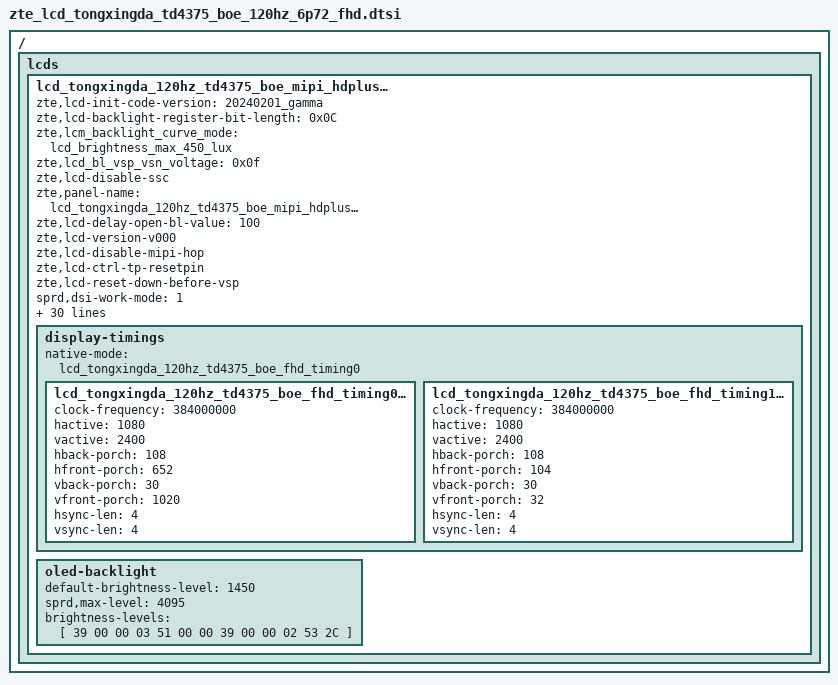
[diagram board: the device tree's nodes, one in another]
/ {
	fragment {
		target-path = "/";
		__overlay__ {
			lcds {
				lcd_tongxingda_120hz_td4375_boe_mipi_hdplus_omnivision: lcd_tongxingda_120hz_td4375_boe_mipi_hdplus_omnivision {
					zte,lcd-init-code-version = "20240201_gamma";

					zte,lcd-backlight-register-bit-length = <0x0C>;
					zte,lcm_backlight_curve_mode = "lcd_brightness_max_450_lux";
					zte,lcd_bl_vsp_vsn_voltage = <0x0f>;
					zte,lcd-disable-ssc;
					zte,panel-name = "lcd_tongxingda_120hz_td4375_boe_mipi_hdplus_omnivision";
					zte,lcd-delay-open-bl-value = <100>;
					zte,lcd-version-v000;
					zte,lcd-disable-mipi-hop;
					zte,lcd-ctrl-tp-resetpin;
					zte,lcd-reset-down-before-vsp;

					sprd,dsi-work-mode = <1>;
					sprd,dsi-lane-number = <4>;
					sprd,dsi-color-format = "dsc";
					sprd,phy-bit-clock = <1100000>;
					sprd,phy-escape-clock = <20000>;/* kHz */

					sprd,width-mm = <70081>;
					sprd,height-mm = <155736>;
					sprd,vrr-enabled;
					sprd,vrr-max-layers = <3>;
					sprd,slice-width = <540>;
					sprd,slice-height = <12>;
					sprd,output-bpc = <8>;
					sprd,dsc-enable = <1>;
					sprd,dual-dsi-enable = <0>;

					sprd,esd-check-enable = <1>;/* 0:close , 1:open */
					sprd,esd-check-mode = <1>;/* 0:REG ,1:TE  */
					sprd,esd-check-period = <2000>;
					sprd,esd-check-register = <0x0A>;
					sprd,esd-check-value = <0x9C>;

					sprd,dphy-taget-val = <5>;

					sprd,reset-on-sequence = <1 5>, <0 15>, <1 25>;
					sprd,reset-off-sequence = <0 20>;

					sprd,use-gen-write;
					sprd,initial-command = [
39 00 00 02 B0 00
39 00 00 0B B6 30 6B 00 86 03 0A 13 1A 00 00
39 00 00 05 B7 51 00 00 00
39 00 00 08 B8 57 3D 19 BE 1E 0A 0A
39 00 00 08 B9 6F 3D 28 BE 3C 14 0A
39 00 00 08 BA 33 57 00 00 00 00 0A
39 00 00 0C BB 44 26 C3 1F 19 06 03 C0 00 00 10
39 00 00 0C BC 32 4C C3 52 32 1F 03 F2 00 00 13
39 00 00 0C BD 24 68 C3 AA 3F 32 03 FF 00 00 25
39 00 00 0D BE 00 00 00 00 00 00 00 00 00 00 00 00
39 00 00 18 C0 00 60 01 2C 14 09 60 03 B6 22 00 08 00 70 00 00 00 00 00 00 00 00 02
39 00 00 35 C1 30 00 00 81 00 00 00 00 22 00 05 20 00 80 FA 40 00 84 0F 00 00 00 00 00 00 00 00 00 00 00 00 00 00 00 00 00 00 00 00 00 00 01 2C 08 08 00 09 C4 0D 66 14 50
39 00 00 8E C2 00 50 5D 02 02 10 03 05 00 00 00 00 00 00 00 00 00 00 00 00 00 00 00 00 00 00 00 00 30 5D 04 04 01 01 C1 00 A0 0A 00 00 02 08 00 00 00 00 11 00 A0 0A 04 00 00 00 00 00 00 00 00 00 00 00 00 00 00 00 00 00 00 00 00 00 11 00 00 00 00 00 00 00 00 00 00 00 00 00 00 00 00 00 00 00 00 00 00 00 11 00 00 00 00 00 00 00 00 00 00 00 00 00 00 00 00 00 00 00 00 00 00 00 11 00 00 00 00 00 00 00 00 00 00 00 00 00 00 00 00 00 00 00 00
39 00 00 6D C3 00 00 61 01 00 00 04 00 00 00 00 00 CE 01 00 0A 01 00 00 00 00 00 00 00 00 00 00 00 00 00 00 00 00 00 00 00 00 00 00 00 00 00 00 00 00 00 00 00 00 00 00 00 00 00 00 00 00 00 00 00 00 00 AA AA AA 00 00 00 00 00 00 01 00 01 00 00 02 00 00 C0 00 08 00 50 00 00 01 00 00 C0 00 08 00 50 00 00 01 00 00 C0 00 00 00 00 00 00 00 00
39 00 00 6E C4 00 00 00 61 5F 5D 00 0F 0E 11 10 00 4F BF 00 53 00 BE 4D 4D 44 03 02 51 00 00 00 61 5F 5D 00 0F 0E 11 10 00 4F BF 00 53 00 BE 4D 4D 44 03 02 51 FF FF FF FF FF FF B8 87 7C B8 87 7C 00 30 82 00 30 82 38 00 00 38 00 00 00 00 00 00 00 00 00 00 00 00 00 00 00 00 00 00 00 58 55 00 00 00 00 00 00 00 00 00 00 00 00 00 00 00 00 00 00
39 00 00 06 C5 08 00 00 00 00
39 00 00 3F C6 02 0A 08 FC FF FF FF 00 00 13 01 AF 00 01 05 1C 1C 1C 00 00 00 34 05 09 28 28 01 05 1C 1C 1C 01 0B 00 00 00 1E 01 00 00 00 00 00 00 20 20 00 00 00 00 00 00 00 00 22 22 00 00 00 00 10 00
39 00 00 0F CB 20 80 70 00 20 00 00 2D 41 00 00 00 00 FF
39 00 00 02 CD 00
39 00 00 24 CE 75 40 49 53 59 5E 63 68 6E 74 7E 8A 98 A8 BB D0 E7 FF 00 6D 02 02 45 04 69 5A 40 51 F4 00 00 84 FA 00 00
39 00 00 07 CF 89 00 80 46 61 00
39 00 00 13 D0 CC 1E D5 66 09 B0 00 CF EF E5 D4 0B 52 FE 09 09 CF 00
39 00 00 2C D1 D7 D7 1B B0 07 07 3B 44 34 44 34 05 33 7B 07 33 3B 78 D2 D2 06 96 13 93 22 22 22 B3 BB 80 00 BB BB 11 08 08 84 C0 09 77 FF 11 44
39 00 00 03 D2 00 00
39 00 00 18 D4 00 00 00 00 00 00 00 00 00 00 00 00 00 00 00 00 00 00 00 00 00 00 00
39 00 00 4B D7 21 10 52 52 00 60 00 0C 00 60 04 FD 01 00 03 00 05 05 00 03 04 05 00 04 00 08 02 08 06 03 08 04 08 10 0C 0B 0A 0A 0A 07 07 06 06 00 08 08 04 05 09 00 04 04 04 04 04 04 04 02 04 04 04 04 04 04 04 04 04 04 06 06 05 05 05 00
39 00 00 3F D8 00 12 00 00 00 00 00 00 00 00 00 00 00 00 00 00 00 00 00 00 00 00 00 00 00 00 00 00 00 00 00 00 00 00 00 00 00 00 00 00 00 00 00 00 00 00 00 00 00 00 00 00 00 00 00 00 00 00 00 00 00 00
39 00 00 17 D9 40 99 26 ED 16 6C 16 6C 16 6C 00 14 00 14 00 14 01 0C 00 00 01 00
39 00 00 05 DD 30 06 23 65
39 00 00 0B DE 00 00 00 0F FF 00 00 00 00 10
39 00 00 0B E6 00 00 00 00 00 00 00 00 00 00
39 00 00 B7 E7 11 00 89 30 80 09 60 04 38 00 0C 02 1C 02 1C 02 00 02 0E 20 01 1F 00 07 0C 08 BB 08 7A 18 00 10 F0 03 0C 20 00 06 0B 0B 33 0E 1C 2A 38 46 54 62 69 70 77 79 7B 7D 7E 01 02 01 00 09 40 09 BE 19 FC 19 FA 19 F8 1A 38 1A 78 1A B6 2A F6 2B 34 2B 74 3B 74 6B F4 00 00 00 00 00 00 11 00 89 30 80 09 60 04 38 00 0C 02 1C 02 1C 02 00 02 0E 20 01 1F 00 07 0C 08 BB 08 7A 18 00 10 F0 03 0C 20 00 06 0B 0B 33 0E 1C 2A 38 46 54 62 69 70 77 79 7B 7D 7E 01 02 01 00 09 40 09 BE 19 FC 19 FA 19 F8 1A 38 1A 78 1A B6 2A F6 2B 34 2B 74 3B 74 6B F4 00 00 00 00 00 00
39 00 00 05 E8 00 30 63 00
39 00 00 1F EA 01 0E 02 00 0F 00 00 00 19 0A 01 AB 00 00 00 00 00 00 00 00 04 C2 00 12 00 60 06 00 86 00
39 00 00 08 EB 00 00 00 00 01 00 11
39 00 00 0B EC 03 70 00 10 82 0F 00 00 02 3A
39 00 00 21 ED 01 01 02 02 00 00 00 00 00 00 00 00 02 00 00 00 00 00 00 00 00 00 00 D0 00 00 00 00 00 EC 10 00
39 00 00 61 EE 03 1F 00 00 00 F5 01 00 00 00 00 C2 4F 7D F0 03 00 00 00 00 00 00 00 00 4F 3D F0 01 10 09 09 09 09 00 00 00 00 00 00 00 01 00 00 00 00 00 00 00 00 00 00 00 00 00 00 1F 00 00 00 00 00 00 00 00 00 00 00 00 00 00 00 00 00 00 00 00 00 00 00 00 00 00 00 00 00 00 00 00 00 00 00 00 00 00 00 00
39 00 00 54 EF 00 90 25 04 10 00 00 00 00 18 18 18 00 00 00 00 00 00 00 00 00 00 90 25 04 10 18 18 18 00 00 00 00 00 00 10 02 10 00 00 10 00 10 00 0A 06 40 00 00 00 00 4B 00 03 51 00 00 05 00 00 00 00 00 00 00 00 00 00 00 00 00 00 00 00 00 00 00 00 00 00 02 00 00
39 00 00 17 F1 00 00 00 00 00 00 00 00 00 00 00 00 00 00 00 00 00 00 00 00 00 00
39 00 00 09 F9 44 3F 00 8D BF 00 09 1D
39 00 00 02 B0 04
39 00 00 4D C7 00 00 00 B7 01 22 01 47 01 60 01 68 01 73 01 6F 01 89 01 58 01 AA 01 69 01 AA 01 61 01 C8 01 BC 02 32 02 9F 02 AD 00 00 00 B7 01 22 01 47 01 60 01 68 01 73 01 6F 01 89 01 58 01 AA 01 69 01 AA 01 61 01 C8 01 BC 02 32 02 9F 02 AD
39 00 00 02 B0 03
39 00 00 03 51 00 00
39 00 00 02 53 2C
39 00 00 02 55 00
39 00 00 02 35 00
05 78 00 02 11 00
05 14 00 02 29 00
					];

					zte,initial-command-fps120 = [
39 00 00 02 B0 00
39 00 00 0B B6 30 6B 00 86 03 0A 13 1A 00 00
39 00 00 05 B7 51 00 00 00
39 00 00 08 B8 57 3D 19 BE 1E 0A 0A
39 00 00 08 B9 6F 3D 28 BE 3C 14 0A
39 00 00 08 BA 33 57 00 00 00 00 0A
39 00 00 0C BB 44 26 C3 1F 19 06 03 C0 00 00 10
39 00 00 0C BC 32 4C C3 52 32 1F 03 F2 00 00 13
39 00 00 0C BD 24 68 C3 AA 3F 32 03 FF 00 00 25
39 00 00 0D BE 00 00 00 00 00 00 00 00 00 00 00 00
39 00 00 18 C0 00 60 01 2C 14 09 60 03 B6 22 00 08 00 70 00 00 00 00 00 00 00 00 02
39 00 00 35 C1 30 00 00 81 00 00 00 00 22 00 05 20 00 80 FA 40 00 84 0F 00 00 00 00 00 00 00 00 00 00 00 00 00 00 00 00 00 00 00 00 00 00 01 2C 08 08 00 09 C4 0D 66 14 50
39 00 00 8E C2 00 50 5D 02 02 10 03 05 00 00 00 00 00 00 00 00 00 00 00 00 00 00 00 00 00 00 00 00 30 5D 04 04 01 01 C1 00 A0 0A 00 00 02 08 00 00 00 00 11 00 A0 0A 04 00 00 00 00 00 00 00 00 00 00 00 00 00 00 00 00 00 00 00 00 00 11 00 00 00 00 00 00 00 00 00 00 00 00 00 00 00 00 00 00 00 00 00 00 00 11 00 00 00 00 00 00 00 00 00 00 00 00 00 00 00 00 00 00 00 00 00 00 00 11 00 00 00 00 00 00 00 00 00 00 00 00 00 00 00 00 00 00 00 00
39 00 00 6D C3 00 00 61 01 00 00 04 00 00 00 00 00 CE 01 00 0A 01 00 00 00 00 00 00 00 00 00 00 00 00 00 00 00 00 00 00 00 00 00 00 00 00 00 00 00 00 00 00 00 00 00 00 00 00 00 00 00 00 00 00 00 00 00 AA AA AA 00 00 00 00 00 00 01 00 01 00 00 02 00 00 C0 00 08 00 50 00 00 01 00 00 C0 00 08 00 50 00 00 01 00 00 C0 00 00 00 00 00 00 00 00
39 00 00 6E C4 00 00 00 61 5F 5D 00 0F 0E 11 10 00 4F BF 00 53 00 BE 4D 4D 44 03 02 51 00 00 00 61 5F 5D 00 0F 0E 11 10 00 4F BF 00 53 00 BE 4D 4D 44 03 02 51 FF FF FF FF FF FF B8 87 7C B8 87 7C 00 30 82 00 30 82 38 00 00 38 00 00 00 00 00 00 00 00 00 00 00 00 00 00 00 00 00 00 00 58 55 00 00 00 00 00 00 00 00 00 00 00 00 00 00 00 00 00 00
39 00 00 06 C5 08 00 00 00 00
39 00 00 3F C6 02 0A 08 FC FF FF FF 00 00 13 01 AF 00 01 05 1C 1C 1C 00 00 00 34 05 09 28 28 01 05 1C 1C 1C 01 0B 00 00 00 1E 01 00 00 00 00 00 00 20 20 00 00 00 00 00 00 00 00 22 22 00 00 00 00 10 00
39 00 00 0F CB 20 80 70 00 20 00 00 2D 41 00 00 00 00 FF
39 00 00 02 CD 00
39 00 00 24 CE 75 40 49 53 59 5E 63 68 6E 74 7E 8A 98 A8 BB D0 E7 FF 00 6D 04 04 45 04 69 5A 40 51 F4 00 00 84 FA 00 00
39 00 00 07 CF 89 00 80 46 61 00
39 00 00 13 D0 CC 1E D5 66 09 B0 00 CF EF E5 D4 0B 52 FE 09 09 CF 00
39 00 00 2C D1 D7 D7 1B B0 07 07 3B 44 34 44 34 05 33 7B 07 33 3B 78 D2 D2 06 96 13 93 22 22 22 B3 BB 80 00 BB BB 11 08 08 84 C0 09 77 FF 11 44
39 00 00 03 D2 00 00
39 00 00 18 D4 00 00 00 00 00 00 00 00 00 00 00 00 00 00 00 00 00 00 00 00 00 00 00
39 00 00 4B D7 21 10 52 52 00 60 00 0C 00 60 04 FD 01 00 03 00 05 05 00 03 04 05 00 04 00 08 02 08 06 03 08 04 08 10 0C 0B 0A 0A 0A 07 07 06 06 00 08 08 04 05 09 00 04 04 04 04 04 04 04 02 04 04 04 04 04 04 04 04 04 04 06 06 05 05 05 00
39 00 00 3F D8 00 12 00 00 00 00 00 00 00 00 00 00 00 00 00 00 00 00 00 00 00 00 00 00 00 00 00 00 00 00 00 00 00 00 00 00 00 00 00 00 00 00 00 00 00 00 00 00 00 00 00 00 00 00 00 00 00 00 00 00 00 00
39 00 00 17 D9 40 99 26 ED 16 6C 16 6C 16 6C 00 14 00 14 00 14 01 0C 00 00 01 00
39 00 00 05 DD 30 06 23 65
39 00 00 0B DE 00 00 00 0F FF 00 00 00 00 10
39 00 00 0B E6 00 00 00 00 00 00 00 00 00 00
39 00 00 B7 E7 11 00 89 30 80 09 60 04 38 00 0C 02 1C 02 1C 02 00 02 0E 20 01 1F 00 07 0C 08 BB 08 7A 18 00 10 F0 03 0C 20 00 06 0B 0B 33 0E 1C 2A 38 46 54 62 69 70 77 79 7B 7D 7E 01 02 01 00 09 40 09 BE 19 FC 19 FA 19 F8 1A 38 1A 78 1A B6 2A F6 2B 34 2B 74 3B 74 6B F4 00 00 00 00 00 00 11 00 89 30 80 09 60 04 38 00 0C 02 1C 02 1C 02 00 02 0E 20 01 1F 00 07 0C 08 BB 08 7A 18 00 10 F0 03 0C 20 00 06 0B 0B 33 0E 1C 2A 38 46 54 62 69 70 77 79 7B 7D 7E 01 02 01 00 09 40 09 BE 19 FC 19 FA 19 F8 1A 38 1A 78 1A B6 2A F6 2B 34 2B 74 3B 74 6B F4 00 00 00 00 00 00
39 00 00 05 E8 00 30 63 00
39 00 00 1F EA 01 0E 02 00 0F 00 00 00 19 0A 01 AB 00 00 00 00 00 00 00 00 04 C2 00 12 00 60 06 00 86 00
39 00 00 08 EB 00 00 00 00 01 00 11
39 00 00 0B EC 03 70 00 10 82 0F 00 00 02 3A
39 00 00 21 ED 01 01 02 02 00 00 00 00 00 00 00 00 02 00 00 00 00 00 00 00 00 00 00 D0 00 00 00 00 00 EC 10 00
39 00 00 61 EE 03 1F 00 00 00 F5 01 00 00 00 00 C2 4F 7D F0 03 00 00 00 00 00 00 00 00 4F 3D F0 01 10 09 09 09 09 00 00 00 00 00 00 00 01 00 00 00 00 00 00 00 00 00 00 00 00 00 00 1F 00 00 00 00 00 00 00 00 00 00 00 00 00 00 00 00 00 00 00 00 00 00 00 00 00 00 00 00 00 00 00 00 00 00 00 00 00 00 00 00
39 00 00 54 EF 00 90 25 04 10 00 00 00 00 18 18 18 00 00 00 00 00 00 00 00 00 00 90 25 04 10 18 18 18 00 00 00 00 00 00 10 02 10 00 00 10 00 10 00 0A 06 40 00 00 00 00 4B 00 03 51 00 00 05 00 00 00 00 00 00 00 00 00 00 00 00 00 00 00 00 00 00 00 00 00 00 02 00 00
39 00 00 17 F1 00 00 00 00 00 00 00 00 00 00 00 00 00 00 00 00 00 00 00 00 00 00
39 00 00 09 F9 44 3F 00 8D BF 00 09 1D
39 00 00 02 B0 04
39 00 00 4D C7 00 00 00 B7 01 22 01 47 01 60 01 68 01 73 01 6F 01 89 01 58 01 AA 01 69 01 AA 01 61 01 C8 01 BC 02 32 02 9F 02 AD 00 00 00 B7 01 22 01 47 01 60 01 68 01 73 01 6F 01 89 01 58 01 AA 01 69 01 AA 01 61 01 C8 01 BC 02 32 02 9F 02 AD
39 00 00 02 B0 03
39 00 00 03 51 00 00
39 00 00 02 53 2C
39 00 00 02 55 00
39 00 00 02 35 00
05 78 00 02 11 00
05 14 00 02 29 00
					];

					sprd,sleep-in-command = [
						15 0A 00 01 28
						15 C8 00 01 10
						];
					sprd,sleep-out-command = [
						05 78 00 01 11
						05 14 00 01 29
						];
					display-timings {
						native-mode = <&lcd_tongxingda_120hz_td4375_boe_fhd_timing0>;
						lcd_tongxingda_120hz_td4375_boe_fhd_timing0: timing0 {
							clock-frequency = <384000000>;
							hactive = <1080>;
							vactive = <2400>;
							hback-porch = <108>;
							hfront-porch = <652>;
							vback-porch = <30>;
							vfront-porch = <1020>;
							hsync-len = <4>;
							vsync-len = <4>;
						};
						lcd_tongxingda_120hz_td4375_boe_fhd_timing1: timing1 {
							clock-frequency = <384000000>;
							hactive = <1080>;
							vactive = <2400>;
							hback-porch = <108>;
							hfront-porch = <104>;
							vback-porch = <30>;
							vfront-porch = <32>;
							hsync-len = <4>;
							vsync-len = <4>;
						};
					};
					oled-backlight {
						default-brightness-level = <1450>;
						sprd,max-level = <4095>;
						brightness-levels = [
							39 00 00 03 51 00 00
							39 00 00 02 53 2C
						];
					};
				};
			};
		};
	};
};
